# CSYS__Compact_System_Module_2 register map
Vendor: Texas Instruments
Peripheral module from a debugger description file (folder msp430).
Registers are 16-bit, access not given, no defined reset value unless marked. A register's access mark holds for its fields unless they carry their own. Offsets are as the file gives them; lines under a group give offsets from that group; [hi:lo] are bit positions; {n}, {i} and the like mark numbered series; 'fields as' and 'values as' point back to an identical list; <NAME> marks a mode.

## CSYS_Compact_System_Module
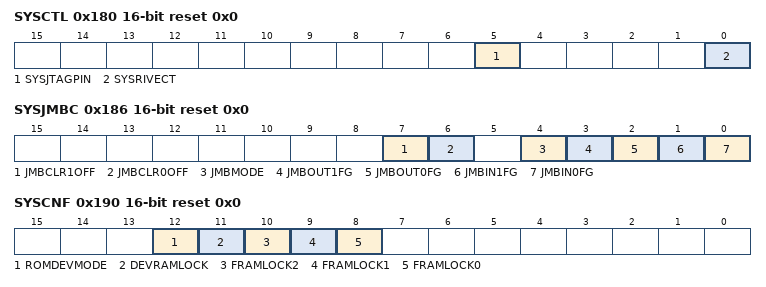
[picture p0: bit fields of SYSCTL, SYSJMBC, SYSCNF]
0x180 SYSCTL rw reset 0x0 — System control
  [5] SYSJTAGPIN — SYS - Dedicated JTAG pins enabled
  [0] SYSRIVECT — SYS - RAM based interrupt vectors
0x186 SYSJMBC rw reset 0x0 — JTAG mailbox control
  [7] JMBCLR1OFF — SYS - Incoming JTAG Mailbox 1 Flag auto-clear disalbe
  [6] JMBCLR0OFF — SYS - Incoming JTAG Mailbox 0 Flag auto-clear disalbe
  [4] JMBMODE — SYS - JMB 16/32 Bit Mode
  [3] JMBOUT1FG — SYS - Outgoing JTAG Mailbox 1 Flag
  [2] JMBOUT0FG — SYS - Outgoing JTAG Mailbox 0 Flag
  [1] JMBIN1FG — SYS - Incoming JTAG Mailbox 1 Flag
  [0] JMBIN0FG — SYS - Incoming JTAG Mailbox 0 Flag
0x188 SYSJMBI0 — JTAG mailbox input 0
0x18A SYSJMBI1 — JTAG mailbox input 1
0x18C SYSJMBO0 — JTAG mailbox output 0
0x18E SYSJMBO1 — JTAG mailbox output 1
0x190 SYSCNF rw reset 0x0 — System Configuration Register
  [12] ROMDEVMODE — SYS - Enable ROM Developent mode
  [11] DEVRAMLOCK — SYS - Write protect Re-Mapped ROM development area
  [10] FRAMLOCK2 — SYS - FRAM Write protect area 2
  [9] FRAMLOCK1 — SYS - FRAM Write protect area 1
  [8] FRAMLOCK0 — SYS - FRAM Write protect area 0
0x198 SYSBERRIV — Bus Error vector generator
0x19A SYSUNIV — User NMI vector generator
0x19C SYSSNIV — System NMI vector generator
0x19E SYSRSTIV — Reset vector generator
